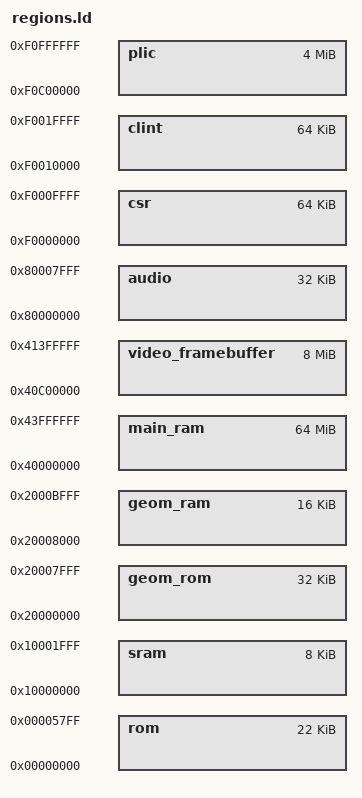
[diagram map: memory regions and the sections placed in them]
MEMORY {
	plic : ORIGIN = 0xf0c00000, LENGTH = 0x00400000
	clint : ORIGIN = 0xf0010000, LENGTH = 0x00010000
	rom : ORIGIN = 0x00000000, LENGTH = 0x00005800
	sram : ORIGIN = 0x10000000, LENGTH = 0x00002000
	main_ram : ORIGIN = 0x40000000, LENGTH = 0x04000000
	video_framebuffer : ORIGIN = 0x40c00000, LENGTH = 0x00800000
	geom_rom : ORIGIN = 0x20000000, LENGTH = 0x00008000
	geom_ram : ORIGIN = 0x20008000, LENGTH = 0x00004000
	audio : ORIGIN = 0x80000000, LENGTH = 0x00008000
	csr : ORIGIN = 0xf0000000, LENGTH = 0x00010000
}
